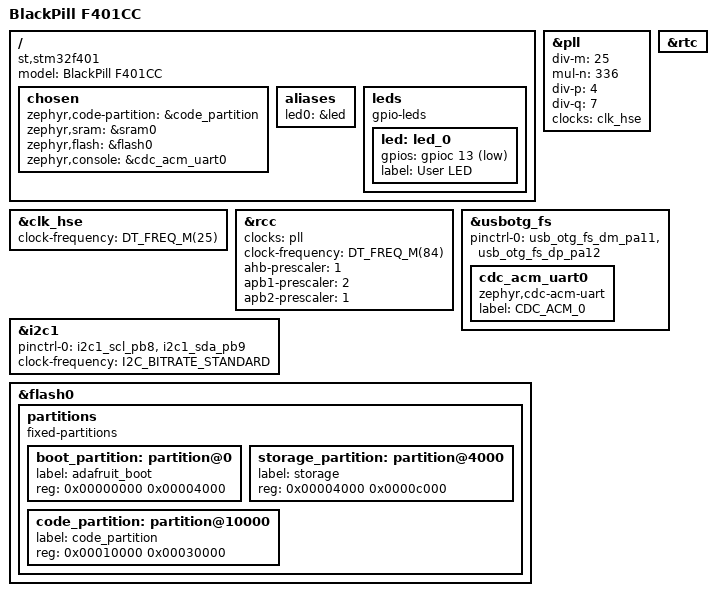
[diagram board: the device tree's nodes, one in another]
/*
 * Copyright (c) 2022 The ZMK Contributors
 *
 * SPDX-License-Identifier: MIT
 */

/dts-v1/;
#include <st/f4/stm32f401Xc.dtsi>
#include <st/f4/stm32f401c(b-c)ux-pinctrl.dtsi>

/ {
    model = "BlackPill F401CC";
    compatible = "st,stm32f401";

    chosen {
        zephyr,code-partition = &code_partition;
        zephyr,sram = &sram0;
        zephyr,flash = &flash0;
        zephyr,console = &cdc_acm_uart0;
    };

    aliases {
        led0 = &led;
    };

    leds {
        compatible = "gpio-leds";
        led: led_0 {
            gpios = <&gpioc 13 GPIO_ACTIVE_LOW>;
            label = "User LED";
        };
    };
};

&clk_hse {
    clock-frequency = <DT_FREQ_M(25)>;
    status = "okay";
};

&pll {
    div-m = <25>;
    mul-n = <336>;
    div-p = <4>;
    div-q = <7>;
    clocks = <&clk_hse>;
    status = "okay";
};

&rcc {
    clocks = <&pll>;
    clock-frequency = <DT_FREQ_M(84)>;
    ahb-prescaler = <1>;
    apb1-prescaler = <2>;
    apb2-prescaler = <1>;
};

&rtc {
    status = "okay";
};

&usbotg_fs {
    pinctrl-0 = <&usb_otg_fs_dm_pa11 &usb_otg_fs_dp_pa12>;
    pinctrl-names = "default";
    status = "okay";
    cdc_acm_uart0: cdc_acm_uart0 {
        compatible = "zephyr,cdc-acm-uart";
        label = "CDC_ACM_0";
    };
};

&i2c1 {
    pinctrl-0 = <&i2c1_scl_pb8 &i2c1_sda_pb9>;
    pinctrl-names = "default";
    clock-frequency = <I2C_BITRATE_STANDARD>;
};

&flash0 {
    partitions {
        compatible = "fixed-partitions";
        #address-cells = <1>;
        #size-cells = <1>;

        boot_partition: partition@0 {
            label = "adafruit_boot";
            reg = <0x00000000 0x00004000>;
        };

        storage_partition: partition@4000 {
            label = "storage";
            reg = <0x00004000 0x0000c000>;
        };

        code_partition: partition@10000 {
            label = "code_partition";
            reg = <0x00010000 0x00030000>;
        };
    };
};
